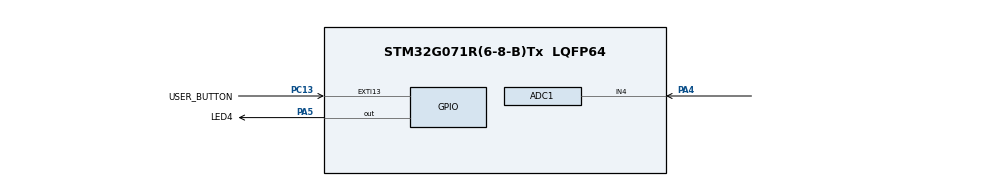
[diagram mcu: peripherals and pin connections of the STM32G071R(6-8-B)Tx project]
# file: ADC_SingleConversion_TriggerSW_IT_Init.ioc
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ADC1.Channel-10\#ChannelRegularConversion=ADC_CHANNEL_4
ADC1.Channel-4\#ChannelRegularConversion=ADC_CHANNEL_4
ADC1.Channel-IN4=ADC_CHANNEL_4
ADC1.ClockPrescaler=ADC_CLOCK_SYNC_PCLK_DIV4
ADC1.EOCSelection=ADC_EOC_SEQ_CONV
ADC1.Overrun=ADC_OVR_DATA_OVERWRITTEN
ADC1.SamplingTime-4\#ChannelRegularConversion=ADC_SAMPLINGTIME_COMMON_1
ADC1.SamplingTimeCommon1=ADC_SAMPLETIME_39CYCLES_5
ADC1.SamplingTimeCommon2=ADC_SAMPLETIME_39CYCLES_5
ADC1.SelectedChannel=ADC_CHANNEL_4
ADC1.master=1
Mcu.Family=STM32G0
Mcu.Name=STM32G071R(6-8-B)Tx
Mcu.Package=LQFP64
NVIC.EXTI4_15_IRQn=true\:3\:0\:true\:false\:true\:true\:true\:true
PA4.GPIO_Mode=GPIO_MODE_ANALOG
PA4.Mode=IN4
PA4.Signal=ADC1_IN4
PA5.GPIO_Label=LED4
PA5.Signal=GPIO_Output
PC13.GPIO_Label=USER_BUTTON
PC13.GPIO_ModeDefaultEXTI=GPIO_MODE_IT_FALLING
PC13.GPIO_PuPd=GPIO_PULLUP
PC13.Signal=GPXTI13
ProjectManager.HeapSize=0x200
ProjectManager.StackSize=0x400
ProjectManager.TargetToolchain=EWARM V8.50
RCC.ADCFreq_Value=16000000
RCC.AHBFreq_Value=16000000
RCC.CodegenConfigPeriph=false
RCC.CortexFreq_Value=16000000
RCC.EXTERNAL_CLOCK_VALUE=48000
RCC.HCLKFreq_Value=16000000
RCC.HSE_VALUE=8000000
RCC.HSI_VALUE=16000000
RCC.LSE_VALUE=32768
RCC.PLLM=RCC_PLLM_DIV4
RCC.PLLN=70
RCC.PLLP=RCC_PLLP_DIV10
RCC.PLLQ=RCC_PLLQ_DIV5
RCC.PLLR=RCC_PLLR_DIV5
RCC.SYSCLKFreq_VALUE=16000000
RCC.VCOOutputFreq_Value=280000000
VP_SYS_VS_DBSignals.Mode=DisableDeadBatterySignals
board=custom

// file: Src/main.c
/* USER CODE BEGIN Header */
/**
  ******************************************************************************
  * @file    Examples_LL/ADC/ADC_SingleConversion_TriggerSW_IT_Init/Src/main.c
  * @author  MCD Application Team
  * @brief   This example describes how to use a ADC peripheral to perform
  *          a single ADC conversion of a channel, at each software start.
  *          Example using programming model: interrupt
  *          (for programming models polling or DMA transfer, refer to
  *          other examples).
  *          This example is based on the STM32G0xx ADC LL API;
  *          Peripheral initialization done using LL unitary services functions.
  ******************************************************************************
  * @attention
  *
  * Copyright (c) 2018-2021 STMicroelectronics.
  * All rights reserved.
  *
  * This software is licensed under terms that can be found in the LICENSE file
  * in the root directory of this software component.
  * If no LICENSE file comes with this software, it is provided AS-IS.
  *
  ******************************************************************************
  */
/* USER CODE END Header */
#include "main.h"

/* USER CODE BEGIN PD */

/* Definitions of ADC hardware constraints delays */
/* Note: Only ADC IP HW delays are defined in ADC LL driver driver,           */
/*       not timeout values:                                                  */
/*       Timeout values for ADC operations are dependent to device clock      */
/*       configuration (system clock versus ADC clock),                       */
/*       and therefore must be defined in user application.                   */
/*       Refer to @ref ADC_LL_EC_HW_DELAYS for description of ADC timeout     */
/*       values definition.                                                   */

  /* Timeout values for ADC operations. */
  /* (calibration, enable settling time, disable settling time, ...)          */
  /* Values defined to be higher than worst cases: low clock frequency,       */
  /* maximum prescalers.                                                      */
  /* Unit: ms                                                                 */
  #define ADC_CALIBRATION_TIMEOUT_MS       (   1U)
  #define ADC_ENABLE_TIMEOUT_MS            (   1U)
  #define ADC_DISABLE_TIMEOUT_MS           (   1U)
  #define ADC_STOP_CONVERSION_TIMEOUT_MS   (   1U)
  #define ADC_CONVERSION_TIMEOUT_MS        (4000U)

  /* Delay between ADC end of calibration and ADC enable.                     */
  /* Delay estimation in CPU cycles: Case of ADC enable done                  */
  /* immediately after ADC calibration, ADC clock setting slow                */
  /* (LL_ADC_CLOCK_ASYNC_DIV32). Use a higher delay if ratio                  */
  /* (CPU clock / ADC clock) is above 32.                                     */
  #define ADC_DELAY_CALIB_ENABLE_CPU_CYCLES  (LL_ADC_DELAY_CALIB_ENABLE_ADC_CYCLES * 32)

/* Definitions of environment analog values */
  /* Value of analog reference voltage (Vref+), connected to analog voltage   */
  /* supply Vdda (unit: mV).                                                  */
  #define VDDA_APPLI                       (3300U)

/* Definitions of data related to this example */
  /* Init variable out of expected ADC conversion data range */
  #define VAR_CONVERTED_DATA_INIT_VALUE    (__LL_ADC_DIGITAL_SCALE(LL_ADC_RESOLUTION_12B) + 1)

/* USER CODE END PD */

/* USER CODE BEGIN PV */

/* Variables for ADC conversion data */
__IO uint16_t uhADCxConvertedData = VAR_CONVERTED_DATA_INIT_VALUE; /* ADC group regular conversion data */

/* Variables for ADC conversion data computation to physical values */
__IO uint16_t uhADCxConvertedData_Voltage_mVolt = 0U;  /* Value of voltage calculated from ADC conversion data (unit: mV) */

/* Variable to report status of ADC group regular unitary conversion          */
/*  0: ADC group regular unitary conversion is not completed                  */
/*  1: ADC group regular unitary conversion is completed                      */
/*  2: ADC group regular unitary conversion has not been started yet          */
/*     (initial state)                                                        */
__IO uint8_t ubAdcGrpRegularUnitaryConvStatus = 2U; /* Variable set into ADC interruption callback */

/* USER CODE END PV */

void SystemClock_Config(void);
static void MX_GPIO_Init(void);
static void MX_ADC1_Init(void);
/* USER CODE BEGIN PFP */
void     Activate_ADC(void);
void     LED_On(void);
void     LED_Off(void);
void     LED_Blinking(uint32_t Period);
/* USER CODE END PFP */

int main(void)
{

  /* MCU Configuration--------------------------------------------------------*/

  /* Reset of all peripherals, Initializes the Flash interface and the Systick. */
  LL_APB2_GRP1_EnableClock(LL_APB2_GRP1_PERIPH_SYSCFG);
  LL_APB1_GRP1_EnableClock(LL_APB1_GRP1_PERIPH_PWR);

  /** Disable the internal Pull-Up in Dead Battery pins of UCPD peripheral
  */
  LL_SYSCFG_DisableDBATT(LL_SYSCFG_UCPD1_STROBE | LL_SYSCFG_UCPD2_STROBE);

  /* Configure the system clock */
  SystemClock_Config();

  /* Initialize all configured peripherals */
  MX_GPIO_Init();
  MX_ADC1_Init();
  /* USER CODE BEGIN 2 */

  /* Activate ADC */
  /* Perform ADC activation procedure to make it ready to convert. */
  Activate_ADC();

  /* USER CODE END 2 */

  /* Infinite loop */
  /* USER CODE BEGIN WHILE */
  while (1)
  {
    /* Note: ADC group regular conversion start is done into push button      */
    /*       IRQ handler, refer to function "UserButton_Callback()".          */

    /* Note: LED state depending on ADC conversion status is set into ADC     */
    /*       IRQ handler, refer to function                                   */
    /*       "AdcGrpRegularUnitaryConvComplete_Callback()".                   */

    /* Note: ADC conversion data is stored into variable                      */
    /*       "uhADCxConvertedData".                                           */
    /*       (for debug: see variable content into watch window).             */

    /* Note: ADC conversion data are computed to physical values              */
    /*       into variable "uhADCxConvertedData_Voltage_mVolt"                */
    /*       using ADC LL driver helper macro "__LL_ADC_CALC_DATA_TO_VOLTAGE()". */
    /*       (for debug: see variable content into watch window).             */

    /* USER CODE END WHILE */

  }
}

void SystemClock_Config(void)
{
  /* HSI configuration and activation */
  LL_RCC_HSI_Enable();
  while(LL_RCC_HSI_IsReady() != 1)
  {
  }

  /* Set AHB prescaler*/
  LL_RCC_SetAHBPrescaler(LL_RCC_SYSCLK_DIV_1);

  /* Sysclk activation on the HSI */
  LL_RCC_SetSysClkSource(LL_RCC_SYS_CLKSOURCE_HSI);
  while(LL_RCC_GetSysClkSource() != LL_RCC_SYS_CLKSOURCE_STATUS_HSI)
  {
  }

  /* Set APB1 prescaler*/
  LL_RCC_SetAPB1Prescaler(LL_RCC_APB1_DIV_1);
  LL_Init1msTick(16000000);
  /* Update CMSIS variable (which can be updated also through SystemCoreClockUpdate function) */
  LL_SetSystemCoreClock(16000000);
}

static void MX_ADC1_Init(void)
{

  LL_ADC_InitTypeDef ADC_InitStruct = {0};
  LL_ADC_REG_InitTypeDef ADC_REG_InitStruct = {0};

  LL_GPIO_InitTypeDef GPIO_InitStruct = {0};

  /* Peripheral clock enable */
  LL_APB2_GRP1_EnableClock(LL_APB2_GRP1_PERIPH_ADC);

  LL_IOP_GRP1_EnableClock(LL_IOP_GRP1_PERIPH_GPIOA);
  /**ADC1 GPIO Configuration
  PA4   ------> ADC1_IN4
  */
  GPIO_InitStruct.Pin = LL_GPIO_PIN_4;
  GPIO_InitStruct.Mode = LL_GPIO_MODE_ANALOG;
  GPIO_InitStruct.Pull = LL_GPIO_PULL_NO;
  LL_GPIO_Init(GPIOA, &GPIO_InitStruct);

  /* USER CODE BEGIN ADC1_Init 1 */

  /* Configure NVIC to enable ADC1 interruptions */
  NVIC_SetPriority(ADC1_COMP_IRQn, 0);
  NVIC_EnableIRQ(ADC1_COMP_IRQn);
  /* USER CODE END ADC1_Init 1 */

  /** Configure the global features of the ADC (Clock, Resolution, Data Alignment and number of conversion)
  */

   #define ADC_CHANNEL_CONF_RDY_TIMEOUT_MS ( 1U)
   #if (USE_TIMEOUT == 1)
   uint32_t Timeout ; /* Variable used for Timeout management */
   #endif /* USE_TIMEOUT */

  ADC_InitStruct.Clock = LL_ADC_CLOCK_SYNC_PCLK_DIV4;
  ADC_InitStruct.Resolution = LL_ADC_RESOLUTION_12B;
  ADC_InitStruct.DataAlignment = LL_ADC_DATA_ALIGN_RIGHT;
  ADC_InitStruct.LowPowerMode = LL_ADC_LP_MODE_NONE;
  LL_ADC_Init(ADC1, &ADC_InitStruct);
  LL_ADC_REG_SetSequencerConfigurable(ADC1, LL_ADC_REG_SEQ_CONFIGURABLE);

   /* Poll for ADC channel configuration ready */
   #if (USE_TIMEOUT == 1)
   Timeout = ADC_CHANNEL_CONF_RDY_TIMEOUT_MS;
   #endif /* USE_TIMEOUT */
   while (LL_ADC_IsActiveFlag_CCRDY(ADC1) == 0)
     {
   #if (USE_TIMEOUT == 1)
   /* Check Systick counter flag to decrement the time-out value */
   if (LL_SYSTICK_IsActiveCounterFlag())
     {
   if(Timeout-- == 0)
         {
   Error_Handler();
         }
     }
   #endif /* USE_TIMEOUT */
     }
   /* Clear flag ADC channel configuration ready */
   LL_ADC_ClearFlag_CCRDY(ADC1);
  ADC_REG_InitStruct.TriggerSource = LL_ADC_REG_TRIG_SOFTWARE;
  ADC_REG_InitStruct.SequencerLength = LL_ADC_REG_SEQ_SCAN_DISABLE;
  ADC_REG_InitStruct.SequencerDiscont = LL_ADC_REG_SEQ_DISCONT_DISABLE;
  ADC_REG_InitStruct.ContinuousMode = LL_ADC_REG_CONV_SINGLE;
  ADC_REG_InitStruct.DMATransfer = LL_ADC_REG_DMA_TRANSFER_NONE;
  ADC_REG_InitStruct.Overrun = LL_ADC_REG_OVR_DATA_OVERWRITTEN;
  LL_ADC_REG_Init(ADC1, &ADC_REG_InitStruct);
  LL_ADC_SetOverSamplingScope(ADC1, LL_ADC_OVS_DISABLE);
  LL_ADC_SetTriggerFrequencyMode(ADC1, LL_ADC_CLOCK_FREQ_MODE_HIGH);
  LL_ADC_SetSamplingTimeCommonChannels(ADC1, LL_ADC_SAMPLINGTIME_COMMON_1, LL_ADC_SAMPLINGTIME_39CYCLES_5);
  LL_ADC_SetSamplingTimeCommonChannels(ADC1, LL_ADC_SAMPLINGTIME_COMMON_2, LL_ADC_SAMPLINGTIME_39CYCLES_5);
  LL_ADC_DisableIT_EOC(ADC1);
  LL_ADC_DisableIT_EOS(ADC1);

   /* Enable ADC internal voltage regulator */
   LL_ADC_EnableInternalRegulator(ADC1);
   /* Delay for ADC internal voltage regulator stabilization. */
   /* Compute number of CPU cycles to wait for, from delay in us. */
   /* Note: Variable divided by 2 to compensate partially */
   /* CPU processing cycles (depends on compilation optimization). */
   /* Note: If system core clock frequency is below 200kHz, wait time */
   /* is only a few CPU processing cycles. */
   uint32_t wait_loop_index;
   wait_loop_index = ((LL_ADC_DELAY_INTERNAL_REGUL_STAB_US * (SystemCoreClock / (100000 * 2))) / 10);
   while(wait_loop_index != 0)
     {
   wait_loop_index--;
     }

  /** Configure Regular Channel
  */
  LL_ADC_REG_SetSequencerRanks(ADC1, LL_ADC_REG_RANK_1, LL_ADC_CHANNEL_4);

   /* Poll for ADC channel configuration ready */
   #if (USE_TIMEOUT == 1)
   Timeout = ADC_CHANNEL_CONF_RDY_TIMEOUT_MS;
   #endif /* USE_TIMEOUT */
   while (LL_ADC_IsActiveFlag_CCRDY(ADC1) == 0)
     {
   #if (USE_TIMEOUT == 1)
   /* Check Systick counter flag to decrement the time-out value */
   if (LL_SYSTICK_IsActiveCounterFlag())
     {
   if(Timeout-- == 0)
         {
   Error_Handler();
         }
     }
   #endif /* USE_TIMEOUT */
     }
   /* Clear flag ADC channel configuration ready */
   LL_ADC_ClearFlag_CCRDY(ADC1);
  LL_ADC_SetChannelSamplingTime(ADC1, LL_ADC_CHANNEL_4, LL_ADC_SAMPLINGTIME_COMMON_1);

  /** Configure Regular Channel
  */
  LL_ADC_REG_SetSequencerRanks(ADC1, LL_ADC_REG_RANK_1, LL_ADC_CHANNEL_4);

   /* Poll for ADC channel configuration ready */
   #if (USE_TIMEOUT == 1)
   Timeout = ADC_CHANNEL_CONF_RDY_TIMEOUT_MS;
   #endif /* USE_TIMEOUT */
   while (LL_ADC_IsActiveFlag_CCRDY(ADC1) == 0)
     {
   #if (USE_TIMEOUT == 1)
   /* Check Systick counter flag to decrement the time-out value */
   if (LL_SYSTICK_IsActiveCounterFlag())
     {
   if(Timeout-- == 0)
         {
   Error_Handler();
         }
     }
   #endif /* USE_TIMEOUT */
     }
   /* Clear flag ADC channel configuration ready */
   LL_ADC_ClearFlag_CCRDY(ADC1);
  LL_ADC_SetChannelSamplingTime(ADC1, LL_ADC_CHANNEL_4, LL_ADC_SAMPLINGTIME_COMMON_1);
  /* USER CODE BEGIN ADC1_Init 2 */

  /*## Configuration of ADC interruptions ####################################*/
  /* Enable interruption ADC group regular end of unitary conversion */
  LL_ADC_EnableIT_EOC(ADC1);

  /* Enable interruption ADC group regular overrun */
  LL_ADC_EnableIT_OVR(ADC1);

  /* USER CODE END ADC1_Init 2 */

}

static void MX_GPIO_Init(void)
{
  LL_EXTI_InitTypeDef EXTI_InitStruct = {0};
  LL_GPIO_InitTypeDef GPIO_InitStruct = {0};

  /* GPIO Ports Clock Enable */
  LL_IOP_GRP1_EnableClock(LL_IOP_GRP1_PERIPH_GPIOC);
  LL_IOP_GRP1_EnableClock(LL_IOP_GRP1_PERIPH_GPIOA);

  /**/
  LL_GPIO_ResetOutputPin(LED4_GPIO_Port, LED4_Pin);

  /**/
  LL_EXTI_SetEXTISource(LL_EXTI_CONFIG_PORTC, LL_EXTI_CONFIG_LINE13);

  /**/
  EXTI_InitStruct.Line_0_31 = LL_EXTI_LINE_13;
  EXTI_InitStruct.LineCommand = ENABLE;
  EXTI_InitStruct.Mode = LL_EXTI_MODE_IT;
  EXTI_InitStruct.Trigger = LL_EXTI_TRIGGER_FALLING;
  LL_EXTI_Init(&EXTI_InitStruct);

  /**/
  LL_GPIO_SetPinPull(USER_BUTTON_GPIO_Port, USER_BUTTON_Pin, LL_GPIO_PULL_UP);

  /**/
  LL_GPIO_SetPinMode(USER_BUTTON_GPIO_Port, USER_BUTTON_Pin, LL_GPIO_MODE_INPUT);

  /**/
  GPIO_InitStruct.Pin = LED4_Pin;
  GPIO_InitStruct.Mode = LL_GPIO_MODE_OUTPUT;
  GPIO_InitStruct.Speed = LL_GPIO_SPEED_FREQ_LOW;
  GPIO_InitStruct.OutputType = LL_GPIO_OUTPUT_PUSHPULL;
  GPIO_InitStruct.Pull = LL_GPIO_PULL_NO;
  LL_GPIO_Init(LED4_GPIO_Port, &GPIO_InitStruct);

  /* EXTI interrupt init*/
  NVIC_SetPriority(EXTI4_15_IRQn, 3);
  NVIC_EnableIRQ(EXTI4_15_IRQn);

}

/* USER CODE BEGIN 4 */

/**
  * @brief  Perform ADC activation procedure to make it ready to convert
  *         (ADC instance: ADC1).
  * @note   Operations:
  *         - ADC instance
  *           - Run ADC self calibration
  *           - Enable ADC
  *         - ADC group regular
  *           none: ADC conversion start-stop to be performed
  *                 after this function
  *         - ADC group injected
  *           Feature not available                                  (feature not available on this STM32 series)
  * @param  None
  * @retval None
  */
void Activate_ADC(void)
{
  __IO uint32_t wait_loop_index = 0U;
  __IO uint32_t backup_setting_adc_dma_transfer = 0U;
  #if (USE_TIMEOUT == 1)
  uint32_t Timeout = 0U; /* Variable used for timeout management */
  #endif /* USE_TIMEOUT */

  /*## Operation on ADC hierarchical scope: ADC instance #####################*/

  /* Note: Hardware constraint (refer to description of the functions         */
  /*       below):                                                            */
  /*       On this STM32 series, setting of these features is conditioned to  */
  /*       ADC state:                                                         */
  /*       ADC must be disabled.                                              */
  /* Note: In this example, all these checks are not necessary but are        */
  /*       implemented anyway to show the best practice usages                */
  /*       corresponding to reference manual procedure.                       */
  /*       Software can be optimized by removing some of these checks, if     */
  /*       they are not relevant considering previous settings and actions    */
  /*       in user application.                                               */
  if (LL_ADC_IsEnabled(ADC1) == 0)
  {
    /* Enable ADC internal voltage regulator */
    LL_ADC_EnableInternalRegulator(ADC1);

    /* Delay for ADC internal voltage regulator stabilization.                */
    /* Compute number of CPU cycles to wait for, from delay in us.            */
    /* Note: Variable divided by 2 to compensate partially                    */
    /*       CPU processing cycles (depends on compilation optimization).     */
    /* Note: If system core clock frequency is below 200kHz, wait time        */
    /*       is only a few CPU processing cycles.                             */
    wait_loop_index = ((LL_ADC_DELAY_INTERNAL_REGUL_STAB_US * (SystemCoreClock / (100000 * 2))) / 10);
    while(wait_loop_index != 0)
    {
      wait_loop_index--;
    }

    /* Disable ADC DMA transfer request during calibration */
    /* Note: Specificity of this STM32 series: Calibration factor is          */
    /*       available in data register and also transferred by DMA.          */
    /*       To not insert ADC calibration factor among ADC conversion data   */
    /*       in DMA destination address, DMA transfer must be disabled during */
    /*       calibration.                                                     */
    backup_setting_adc_dma_transfer = LL_ADC_REG_GetDMATransfer(ADC1);
    LL_ADC_REG_SetDMATransfer(ADC1, LL_ADC_REG_DMA_TRANSFER_NONE);

    /* Run ADC self calibration */
    LL_ADC_StartCalibration(ADC1);

    /* Poll for ADC effectively calibrated */
    #if (USE_TIMEOUT == 1)
    Timeout = ADC_CALIBRATION_TIMEOUT_MS;
    #endif /* USE_TIMEOUT */

    while (LL_ADC_IsCalibrationOnGoing(ADC1) != 0)
    {
    #if (USE_TIMEOUT == 1)
      /* Check Systick counter flag to decrement the time-out value */
      if (LL_SYSTICK_IsActiveCounterFlag())
      {
        if(Timeout-- == 0)
        {
        /* Time-out occurred. Set LED to blinking mode */
        LED_Blinking(LED_BLINK_ERROR);
        }
      }
    #endif /* USE_TIMEOUT */
    }

    /* Restore ADC DMA transfer request after calibration */
    LL_ADC_REG_SetDMATransfer(ADC1, backup_setting_adc_dma_transfer);

    /* Delay between ADC end of calibration and ADC enable.                   */
    /* Note: Variable divided by 2 to compensate partially                    */
    /*       CPU processing cycles (depends on compilation optimization).     */
    wait_loop_index = (ADC_DELAY_CALIB_ENABLE_CPU_CYCLES >> 1);
    while(wait_loop_index != 0)
    {
      wait_loop_index--;
    }

    /* Enable ADC */
    LL_ADC_Enable(ADC1);

    /* Poll for ADC ready to convert */
    #if (USE_TIMEOUT == 1)
    Timeout = ADC_ENABLE_TIMEOUT_MS;
    #endif /* USE_TIMEOUT */

    while (LL_ADC_IsActiveFlag_ADRDY(ADC1) == 0)
    {
    #if (USE_TIMEOUT == 1)
      /* Check Systick counter flag to decrement the time-out value */
      if (LL_SYSTICK_IsActiveCounterFlag())
      {
        if(Timeout-- == 0)
        {
        /* Time-out occurred. Set LED to blinking mode */
        LED_Blinking(LED_BLINK_ERROR);
        }
      }
    #endif /* USE_TIMEOUT */
    }

    /* Note: ADC flag ADRDY is not cleared here to be able to check ADC       */
    /*       status afterwards.                                               */
    /*       This flag should be cleared at ADC Deactivation, before a new    */
    /*       ADC activation, using function "LL_ADC_ClearFlag_ADRDY()".       */
  }

  /*## Operation on ADC hierarchical scope: ADC group regular ################*/
  /* Note: No operation on ADC group regular performed here.                  */
  /*       ADC group regular conversions to be performed after this function  */
  /*       using function:                                                    */
  /*       "LL_ADC_REG_StartConversion();"                                    */

  /*## Operation on ADC hierarchical scope: ADC group injected ###############*/
  /* Note: Feature not available on this STM32 series */

}

/**
  * @brief  Turn-on LED4.
  * @param  None
  * @retval None
  */
void LED_On(void)
{
  /* Turn LED4 on */
  LL_GPIO_SetOutputPin(LED4_GPIO_Port, LED4_Pin);
}

/**
  * @brief  Turn-off LED4.
  * @param  None
  * @retval None
  */
void LED_Off(void)
{
  /* Turn LED4 off */
  LL_GPIO_ResetOutputPin(LED4_GPIO_Port, LED4_Pin);
}

/**
  * @brief  Set LED4 to Blinking mode for an infinite loop (toggle period based on value provided as input parameter).
  * @param  Period : Period of time (in ms) between each toggling of LED
  *   This parameter can be user defined values. Pre-defined values used in that example are :
  *     @arg LED_BLINK_FAST : Fast Blinking
  *     @arg LED_BLINK_SLOW : Slow Blinking
  *     @arg LED_BLINK_ERROR : Error specific Blinking
  * @retval None
  */
void LED_Blinking(uint32_t Period)
{
  /* Turn LED4 on */
  LL_GPIO_SetOutputPin(LED4_GPIO_Port, LED4_Pin);

  /* Toggle IO in an infinite loop */
  while (1)
  {
    LL_GPIO_TogglePin(LED4_GPIO_Port, LED4_Pin);
    LL_mDelay(Period);
  }
}

/******************************************************************************/
/*   USER IRQ HANDLER TREATMENT                                               */
/******************************************************************************/

/**
  * @brief  Function to manage IRQ Handler
  * @param  None
  * @retval None
  */
void UserButton_Callback(void)
{
  /* Turn LED off before performing a new ADC conversion start */
  LED_Off();

  /* Reset status variable of ADC group regular unitary conversion before     */
  /* performing a new ADC group regular conversion start.                     */
  /* Note: Optionally, for this example purpose, check ADC unitary            */
  /*       conversion status before starting another ADC conversion.          */

  if (ubAdcGrpRegularUnitaryConvStatus != 0)
  {
    ubAdcGrpRegularUnitaryConvStatus = 0;
  }
  else
  {
    /* Error: Previous action (ADC conversion or DMA transfer) not yet        */
    /* completed.                                                             */
    LED_Blinking(LED_BLINK_ERROR);
  }

  /* Init variable containing ADC conversion data */
  uhADCxConvertedData = VAR_CONVERTED_DATA_INIT_VALUE;

  /* Start ADC group regular conversion */
  /* Note: Hardware constraint (refer to description of the function          */
  /*       below):                                                            */
  /*       On this STM32 series, setting of this feature is conditioned to    */
  /*       ADC state:                                                         */
  /*       ADC must be enabled without conversion on going on group regular,  */
  /*       without ADC disable command on going.                              */
  /* Note: In this example, all these checks are not necessary but are        */
  /*       implemented anyway to show the best practice usages                */
  /*       corresponding to reference manual procedure.                       */
  /*       Software can be optimized by removing some of these checks, if     */
  /*       they are not relevant considering previous settings and actions    */
  /*       in user application.                                               */
  if ((LL_ADC_IsEnabled(ADC1) == 1)               &&
      (LL_ADC_IsDisableOngoing(ADC1) == 0)        &&
      (LL_ADC_REG_IsConversionOngoing(ADC1) == 0)   )
  {
    LL_ADC_REG_StartConversion(ADC1);
  }
  else
  {
    /* Error: ADC conversion start could not be performed */
    LED_Blinking(LED_BLINK_ERROR);
  }
}

/**
  * @brief  ADC group regular end of unitary conversion interruption callback
  * @note   This function is executed when the ADC group regular
  *         sequencer has converted one rank of the sequence.
  *         Therefore, this function is executed as many times as number
  *         of ranks in the sequence.
  * @retval None
  */
void AdcGrpRegularUnitaryConvComplete_Callback()
{
  /* Retrieve ADC conversion data */
  /* (data maximum amplitude corresponds to ADC resolution: 12 bits) */
  uhADCxConvertedData = LL_ADC_REG_ReadConversionData12(ADC1);

  /* Computation of ADC conversions raw data to physical values               */
  /* using LL ADC driver helper macro.                                        */
  uhADCxConvertedData_Voltage_mVolt = __LL_ADC_CALC_DATA_TO_VOLTAGE(VDDA_APPLI, uhADCxConvertedData, LL_ADC_RESOLUTION_12B);

  /* Update status variable of ADC unitary conversion */
  ubAdcGrpRegularUnitaryConvStatus = 1;

  /* Set LED depending on ADC unitary conversion status */
  /* - Turn-on if ADC group regular unitary conversion is completed */
  /* - Turn-off if ADC group regular unitary conversion is not completed */
  LED_On();

}

/**
  * @brief  ADC group regular overrun interruption callback
  * @note   This function is executed when ADC group regular
  *         overrun error occurs.
  * @retval None
  */
void AdcGrpRegularOverrunError_Callback(void)
{
  /* Note: Disable ADC interruption that caused this error before entering in */
  /*       infinite loop below.                                               */

  /* Disable ADC group regular overrun interruption */
  LL_ADC_DisableIT_OVR(ADC1);

  /* Error from ADC */
  LED_Blinking(LED_BLINK_ERROR);
}

/* USER CODE END 4 */

void Error_Handler(void)
{
}
